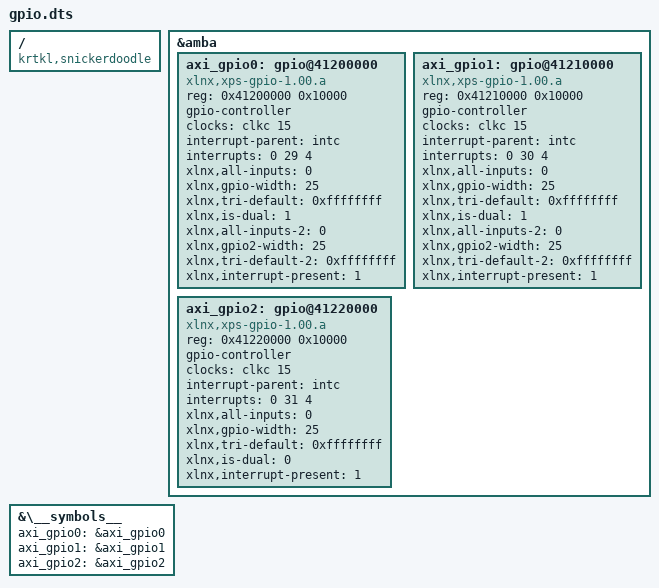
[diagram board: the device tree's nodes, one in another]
/**
 * Copyright (c) 2018 krtkl inc.
 *
 * snickerdoodle AXI GPIO Device Tree Overlay
 *
 * This program is free software; you can redistribute it and/or modify it
 * under the terms of the GNU General Public License version 2 as published by
 * the Free Software Foundation.
 */

/dts-v1/;
/plugin/;

/ {
	compatible = "krtkl,snickerdoodle", "xlnx,zynq-7000";

	fragment@0 {
		target = <&amba>;
		__overlay__ {
			
			#address-cells = <1>;
			#size-cells = <1>;

			axi_gpio0: gpio@41200000 {
				compatible = "xlnx,xps-gpio-1.00.a";
				reg = <0x41200000 0x10000>;
				gpio-controller;
				clock-names = "s_axi_aclk";
				clocks = <&clkc 15>;
				interrupt-parent = <&intc>;
				interrupts = <0 29 4>;		
				#gpio-cells = <2>;
				xlnx,all-inputs = <0>;
				xlnx,gpio-width = <25>;
				xlnx,tri-default = <0xffffffff>;
				xlnx,is-dual = <1>;
				xlnx,all-inputs-2 = <0>;
				xlnx,gpio2-width = <25>;
				xlnx,tri-default-2 = <0xffffffff>;
				xlnx,interrupt-present = <1>;
			};

			axi_gpio1: gpio@41210000 {
				compatible = "xlnx,xps-gpio-1.00.a";
				reg = <0x41210000 0x10000>;
				gpio-controller;
				clock-names = "s_axi_aclk";
				clocks = <&clkc 15>;
				interrupt-parent = <&intc>;
				interrupts = <0 30 4>;
				#gpio-cells = <2>;
				xlnx,all-inputs = <0>;
				xlnx,gpio-width = <25>;
				xlnx,tri-default = <0xffffffff>;
				xlnx,is-dual = <1>;
				xlnx,all-inputs-2 = <0>;
				xlnx,gpio2-width = <25>;
				xlnx,tri-default-2 = <0xffffffff>;
				xlnx,interrupt-present = <1>;
			};

			axi_gpio2: gpio@41220000 {
				compatible = "xlnx,xps-gpio-1.00.a";
				reg = <0x41220000 0x10000>;
				gpio-controller;
				clock-names = "s_axi_aclk";
				clocks = <&clkc 15>;
				interrupt-parent = <&intc>;
				interrupts = <0 31 4>;
				#gpio-cells = <2>;
				xlnx,all-inputs = <0>;
				xlnx,gpio-width = <25>;
				xlnx,tri-default = <0xffffffff>;
				xlnx,is-dual = <0>;
				xlnx,interrupt-present = <1>;
			};
		};
	};

	fragment@1 {
		target-path = "\__symbols__";
		__overlay__ {
			axi_gpio0 = &axi_gpio0;
			axi_gpio1 = &axi_gpio1;
			axi_gpio2 = &axi_gpio2;
		};
	};
};

